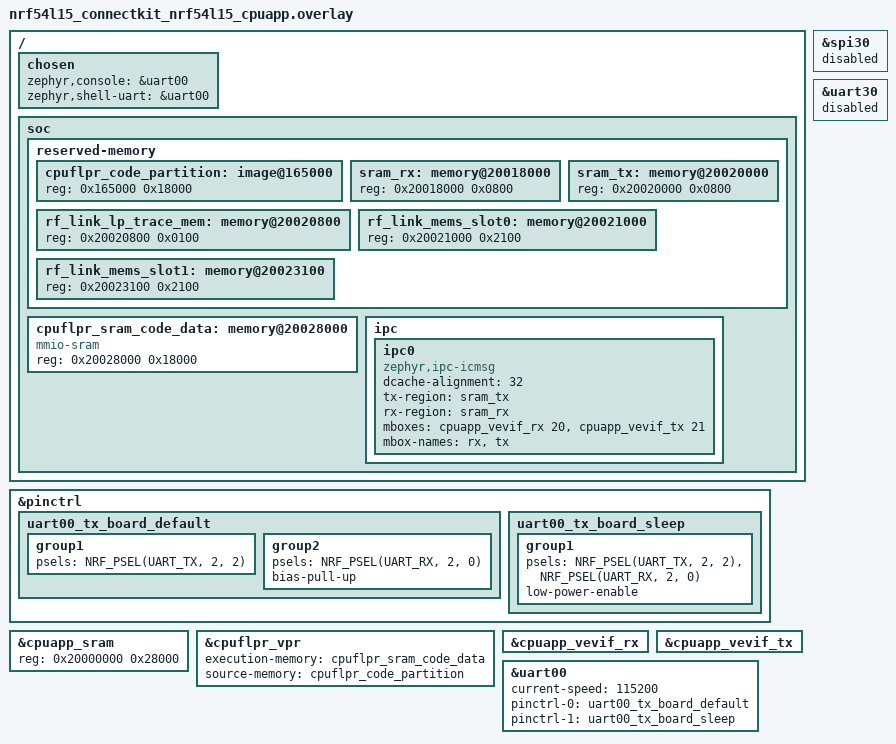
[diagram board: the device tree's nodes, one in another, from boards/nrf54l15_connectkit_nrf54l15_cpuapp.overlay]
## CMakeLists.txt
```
#
# Copyright (c) 2018 Nordic Semiconductor
# Copyright (c) 2016-2025 Makerdiary <https://makerdiary.com>
#
# SPDX-License-Identifier: LicenseRef-Nordic-5-Clause
#
cmake_minimum_required(VERSION 3.20.0)

set(USER_CACHE_DIR "${CMAKE_BINARY_DIR}/zephyr_cache" CACHE PATH "Local build cache")
find_package(Zephyr REQUIRED HINTS $ENV{ZEPHYR_BASE})
project(rf_link_tx)

# NORDIC SDK APP START
target_sources(app PRIVATE
  src/fatal_diag.c
  src/main.c
  src/debug_uart.c
  src/ipc_bridge.c
  src/radio_link.c
)

target_include_directories(app PRIVATE
  src
  ${CMAKE_CURRENT_SOURCE_DIR}/../rf_link_common
)

# NORDIC SDK APP END
```

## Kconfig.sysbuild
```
source "share/sysbuild/Kconfig"
```

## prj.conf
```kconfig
CONFIG_SERIAL=y
CONFIG_CONSOLE=n
CONFIG_UART_CONSOLE=n
CONFIG_PRINTK=n
CONFIG_STDOUT_CONSOLE=n
CONFIG_EARLY_CONSOLE=n
CONFIG_BOOT_BANNER=n
CONFIG_NCS_BOOT_BANNER=n

# Use the non-blocking UARTE async API. On nRF this is backed by EasyDMA.
CONFIG_UART_ASYNC_API=y
CONFIG_UART_00_ASYNC=y

# The custom TX board does not rely on an external 32.768 kHz crystal.
# Match the verified gpio_demo startup clock source so CPUAPP can reach main().
CONFIG_CLOCK_CONTROL_NRF_K32SRC_RC=y
CONFIG_CLOCK_CONTROL_NRF_K32SRC_500PPM=y

CONFIG_MBOX=y
CONFIG_IPC_SERVICE=y
CONFIG_IPC_SERVICE_BACKEND_ICMSG=y
CONFIG_ASSERT=y
CONFIG_CRC=y

CONFIG_ESB=y
CONFIG_ESB_MAX_PAYLOAD_LENGTH=224
CONFIG_ESB_TX_FIFO_SIZE=16
CONFIG_ESB_RX_FIFO_SIZE=16
CONFIG_CLOCK_CONTROL=y
CONFIG_NRFX_DPPI10=y

CONFIG_MAIN_STACK_SIZE=4096
CONFIG_IPC_SERVICE_BACKEND_ICMSG_WQ_STACK_SIZE=4096
CONFIG_PBUF_RX_READ_BUF_SIZE=256
```

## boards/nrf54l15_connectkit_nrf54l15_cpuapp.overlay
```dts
/ {
	chosen {
		zephyr,console = &uart00;
		zephyr,shell-uart = &uart00;
	};

	soc {
		reserved-memory {
			#address-cells = <1>;
			#size-cells = <1>;
			ranges;

			/* FLPR code partition */
			cpuflpr_code_partition: image@165000 {
				reg = <0x165000 0x18000>; /* 96 KB */
			};

			/* ICMSG shared memory: HP receives here */
			sram_rx: memory@20018000 {
				reg = <0x20018000 0x0800>;
			};

			/* ICMSG shared memory: HP transmits here */
			sram_tx: memory@20020000 {
				reg = <0x20020000 0x0800>;
			};

			/* LP runtime trace shared with HP for diagnostics */
			rf_link_lp_trace_mem: memory@20020800 {
				reg = <0x20020800 0x0100>;
			};

			/* Ping-pong MEMS batches written by FLPR and read by CPUAPP. */
			rf_link_mems_slot0: memory@20021000 {
				reg = <0x20021000 0x2100>;
			};

			rf_link_mems_slot1: memory@20023100 {
				reg = <0x20023100 0x2100>;
			};
		};

		/* FLPR execution SRAM */
		cpuflpr_sram_code_data: memory@20028000 {
			compatible = "mmio-sram";
			reg = <0x20028000 0x18000>; /* 96 KB */
			#address-cells = <1>;
			#size-cells = <1>;
			ranges = <0x0 0x20028000 0x18000>;
		};

		ipc {
			ipc0: ipc0 {
				compatible = "zephyr,ipc-icmsg";
				dcache-alignment = <32>;
				tx-region = <&sram_tx>;
				rx-region = <&sram_rx>;
				mboxes = <&cpuapp_vevif_rx 20>, <&cpuapp_vevif_tx 21>;
				mbox-names = "rx", "tx";
				status = "okay";
			};
		};
	};
};

/* TX custom board UART: MCU_UART_RX=P2.00, MCU_UART_TX=P2.02. */
&pinctrl {
	uart00_tx_board_default: uart00_tx_board_default {
		group1 {
			psels = <NRF_PSEL(UART_TX, 2, 2)>;
		};
		group2 {
			psels = <NRF_PSEL(UART_RX, 2, 0)>;
			bias-pull-up;
		};
	};

	uart00_tx_board_sleep: uart00_tx_board_sleep {
		group1 {
			psels = <NRF_PSEL(UART_TX, 2, 2)>,
				<NRF_PSEL(UART_RX, 2, 0)>;
			low-power-enable;
		};
	};
};

&cpuapp_sram {
	reg = <0x20000000 0x28000>; /* 160 KB */
	ranges = <0x0 0x20000000 0x28000>;
};

&cpuflpr_vpr {
	status = "okay";
	execution-memory = <&cpuflpr_sram_code_data>;
	source-memory = <&cpuflpr_code_partition>;
};

&cpuapp_vevif_rx {
	status = "okay";
};

&cpuapp_vevif_tx {
	status = "okay";
};

/* Serial instance 30 is owned by FLPR as SPIM30 for IIM-42352 sampling. */
&spi30 {
	status = "disabled";
};

&uart30 {
	status = "disabled";
};

&uart00 {
	status = "okay";
	current-speed = <115200>;
	pinctrl-0 = <&uart00_tx_board_default>;
	pinctrl-1 = <&uart00_tx_board_sleep>;
	pinctrl-names = "default", "sleep";
	/delete-property/ hw-flow-control;
};
```

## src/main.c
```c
#include <errno.h>
#include <stdint.h>
#include <string.h>
#include <zephyr/cache.h>
#include <zephyr/app_version.h>
#include <zephyr/kernel.h>
#include <zephyr/sys/barrier.h>
#include <zephyr/sys/crc.h>

#include "debug_uart.h"
#include "ipc_bridge.h"
#include "lp_trace.h"
#include "mems_batch.h"
#include "radio_link.h"
#include "rf_link_proto.h"

#define BATCH_RELEASE_TIMEOUT_MS 20u
#define BATCH_RELEASE_RETRIES    3u

struct batch_tx_stats {
	uint32_t batches_received;
	uint32_t batches_sent;
	uint32_t batches_failed;
	uint32_t batch_bad_header;
	uint32_t batch_bad_crc;
	uint32_t frames_attempted;
	uint32_t frames_sent;
	uint32_t frames_failed;
	uint32_t samples_sent;
	uint32_t release_errors;
};

static struct batch_tx_stats batch_stats;
static uint16_t rf_seq;
static bool radio_ready;

static void print_boot_line(void)
{
	debug_uart_puts("\r\nrf_link_tx HP started");
	debug_uart_crlf();
	debug_uart_puts("mode=MEMS_BATCH_ESB_PTX,phy=");
	debug_uart_puts(radio_link_phy_label());
	debug_uart_puts(",ack=");
	debug_uart_puts(RF_LINK_NOACK_STREAM ? "noack" : "ack");
	debug_uart_puts(",channel=");
	debug_uart_u32(RF_LINK_CHANNEL);
	debug_uart_puts(",pipe=");
	debug_uart_u32(RF_LINK_PIPE);
	debug_uart_puts(",prefix=0x54,fw=");
	debug_uart_puts(STRINGIFY(APP_BUILD_VERSION));
	debug_uart_puts(",batch_samples=");
	debug_uart_u32(RF_LINK_MEMS_BATCH_SAMPLE_COUNT);
	debug_uart_puts(",samples_per_frame=");
	debug_uart_u32(RF_LINK_FRAME_SAMPLE_COUNT);
	debug_uart_puts(",sample_hz=");
	debug_uart_u32(RF_LINK_TARGET_SAMPLE_HZ);
	debug_uart_crlf();
}

static void print_status(void)
{
	struct ipc_bridge_stats ipc_stats;
	struct rf_link_lp_trace lp_trace;
	struct radio_link_stats radio_stats = {0};
	bool have_lp_trace;

	ipc_bridge_stats_get(&ipc_stats);
	if (radio_ready) {
		radio_link_stats_get(&radio_stats);
	}
	have_lp_trace = rf_link_lp_trace_snapshot(&lp_trace);

	debug_uart_puts("TX stat batches_rx=");
	debug_uart_u32(batch_stats.batches_received);
	debug_uart_puts(" batches_ok=");
	debug_uart_u32(batch_stats.batches_sent);
	debug_uart_puts(" batch_bad_hdr=");
	debug_uart_u32(batch_stats.batch_bad_header);
	debug_uart_puts(" batches_fail=");
	debug_uart_u32(batch_stats.batches_failed);
	debug_uart_puts(" batch_bad_crc=");
	debug_uart_u32(batch_stats.batch_bad_crc);
	debug_uart_puts(" frames_try=");
	debug_uart_u32(batch_stats.frames_attempted);
	debug_uart_puts(" frames_ok=");
	debug_uart_u32(batch_stats.frames_sent);
	debug_uart_puts(" frames_fail=");
	debug_uart_u32(batch_stats.frames_failed);
	debug_uart_puts(" samples_ok=");
	debug_uart_u32(batch_stats.samples_sent);
	debug_uart_puts(" ipc_bad=");
	debug_uart_u32(ipc_stats.bad_size + ipc_stats.bad_message);
	debug_uart_puts(" ipc_drop=");
	debug_uart_u32(ipc_stats.queue_drop);
	debug_uart_puts(" release_err=");
	debug_uart_u32(batch_stats.release_errors + ipc_stats.release_fail);
	debug_uart_puts(" rf_ok=");
	debug_uart_u32(radio_stats.tx_ok);
	debug_uart_puts(" rf_fail=");
	debug_uart_u32(radio_stats.tx_failed);
	debug_uart_puts(" rf_timeout=");
	debug_uart_u32(radio_stats.tx_timeout);
	debug_uart_puts(" mac_avg_us=");
	debug_uart_u32(radio_stats.mac_latency_avg_us);
	debug_uart_puts(" lp_stage=");
	debug_uart_u32(have_lp_trace ? lp_trace.stage : 0u);
	debug_uart_puts(" lp_batches=");
	debug_uart_u32(have_lp_trace ? lp_trace.batches_ready : 0u);
	debug_uart_puts(" lp_samples=");
	debug_uart_u32(have_lp_trace ? lp_trace.sensor_samples : 0u);
	debug_uart_puts(" lp_irq=");
	debug_uart_u32(have_lp_trace ? lp_trace.sensor_irq_count : 0u);
	debug_uart_puts(" lp_poll=");
	debug_uart_u32(have_lp_trace ? lp_trace.sensor_poll_fallbacks : 0u);
	debug_uart_puts(" lp_malformed=");
	debug_uart_u32(have_lp_trace ? lp_trace.sensor_malformed : 0u);
	debug_uart_puts(" lp_io_err=");
	debug_uart_u32(have_lp_trace ? lp_trace.sensor_io_errors : 0u);
	debug_uart_puts(" lp_fifo_ovf=");
	debug_uart_u32(have_lp_trace ? lp_trace.fifo_overflows : 0u);
	debug_uart_puts(" lp_slot_wait=");
	debug_uart_u32(have_lp_trace ? lp_trace.slot_waits : 0u);
	debug_uart_puts(" lp_fatal=");
	debug_uart_u32(have_lp_trace ? lp_trace.fatal_count : 0u);
	debug_uart_puts(" lp_fatal_reason=");
	debug_uart_u32(have_lp_trace ? lp_trace.fatal_reason : 0u);
	debug_uart_crlf();
}

static int ensure_radio_ready(void)
{
	int ret;

	if (radio_ready) {
		return 0;
	}

	ret = radio_link_init();
	if (ret == 0) {
		radio_ready = true;
		debug_uart_puts("radio ready after first MEMS batch");
		debug_uart_crlf();
	}

	return ret;
}

static bool batch_header_is_valid(
	const volatile struct rf_link_mems_batch *batch,
	const struct rf_link_ipc_message *message)
{
	return batch != NULL && message != NULL &&
	       batch->magic == RF_LINK_MEMS_BATCH_MAGIC &&
	       batch->version == RF_LINK_MEMS_BATCH_VERSION &&
	       batch->slot_index == message->slot_index &&
	       batch->batch_seq == message->batch_seq &&
	       batch->sample_count == RF_LINK_MEMS_BATCH_SAMPLE_COUNT &&
	       batch->sample_crc32 == message->sample_crc32;
}

static int transmit_batch(const struct rf_link_ipc_message *message)
{
	volatile struct rf_link_mems_batch *batch;
	const int16_t *samples;
	uint32_t crc;
	uint32_t offset = 0u;
	int first_error = 0;
	int ret;

	batch = rf_link_mems_batch_slot(message->slot_index);
	if (batch == NULL) {
		batch_stats.batch_bad_header++;
		return -EINVAL;
	}

	(void)sys_cache_data_invd_range((void *)(uintptr_t)batch, sizeof(*batch));
	barrier_dmem_fence_full();
	batch_stats.batches_received++;

	if (!batch_header_is_valid(batch, message)) {
		batch_stats.batch_bad_header++;
		return -EBADMSG;
	}

	samples = (const int16_t *)(uintptr_t)&batch->samples[0];
	crc = crc32_ieee((const uint8_t *)samples, sizeof(batch->samples));
	if (crc != message->sample_crc32) {
		batch_stats.batch_bad_crc++;
		return -EBADMSG;
	}

	ret = ensure_radio_ready();
	if (ret != 0) {
		return ret;
	}

	while (offset < RF_LINK_MEMS_BATCH_SAMPLE_COUNT) {
		struct rf_frame frame = {0};
		uint32_t remaining = RF_LINK_MEMS_BATCH_SAMPLE_COUNT - offset;
		uint32_t frame_samples = MIN(remaining, RF_LINK_FRAME_SAMPLE_COUNT);

		frame.magic = RF_LINK_MAGIC;
		frame.seq = rf_seq++;
		frame.sample_count = (uint16_t)frame_samples;
		frame.flags = RF_LINK_FRAME_FLAGS_MEMS;
		if (offset == 0u) {
			frame.flags |= RF_LINK_FRAME_FLAGS_BATCH_START;
		}
		if (frame_samples == remaining) {
			frame.flags |= RF_LINK_FRAME_FLAGS_BATCH_END;
		}
		frame.timestamp_ms = batch->capture_start_ms +
			(uint32_t)(((uint64_t)offset * 1000u) /
				   RF_LINK_TARGET_SAMPLE_HZ);
		memcpy(frame.samples, &samples[offset],
		       frame_samples * sizeof(frame.samples[0]));

		batch_stats.frames_attempted++;
		ret = radio_link_send_frame(&frame, K_MSEC(5));
		if (ret == 0) {
			batch_stats.frames_sent++;
			batch_stats.samples_sent += frame_samples;
		} else {
			batch_stats.frames_failed++;
			if (first_error == 0) {
				first_error = ret;
			}
		}
		offset += frame_samples;
	}

	if (first_error == 0) {
		batch_stats.batches_sent++;
	} else {
		batch_stats.batches_failed++;
	}

	return first_error;
}

static void release_batch(const struct rf_link_ipc_message *message)
{
	int ret = -EIO;

	for (uint32_t attempt = 0u; attempt < BATCH_RELEASE_RETRIES; attempt++) {
		ret = ipc_bridge_release_batch(message->slot_index, message->batch_seq,
					       K_MSEC(BATCH_RELEASE_TIMEOUT_MS));
		if (ret == 0) {
			return;
		}
	}

	batch_stats.release_errors++;
}

int main(void)
{
	struct rf_link_ipc_message message;
	uint32_t last_status_ms;
	int ret;

	/* The application owns uart00 directly; do not silently continue if it is unavailable. */
	if (!debug_uart_init()) {
		return -ENODEV;
	}
	print_boot_line();
	memset(&batch_stats, 0, sizeof(batch_stats));
	rf_seq = 0u;
	radio_ready = false;

	ret = ipc_bridge_init();
	if (ret != 0) {
		debug_uart_puts("ipc init failed err=");
		debug_uart_i32(ret);
		debug_uart_crlf();
		return ret;
	}

	ret = ipc_bridge_wait_bound(K_FOREVER);
	if (ret != 0) {
		debug_uart_puts("ipc bind failed err=");
		debug_uart_i32(ret);
		debug_uart_crlf();
		return ret;
	}

	debug_uart_puts("LP IPC bound; CPUAPP blocking until a 4096-sample batch is ready");
	debug_uart_crlf();
	last_status_ms = k_uptime_get_32();

	while (1) {
		ret = ipc_bridge_wait_batch(&message, K_FOREVER);
		if (ret != 0) {
			continue;
		}

		ret = transmit_batch(&message);
		if (ret != 0) {
			debug_uart_puts("batch rejected/failed seq=");
			debug_uart_u32(message.batch_seq);
			debug_uart_puts(" err=");
			debug_uart_i32(ret);
			debug_uart_crlf();
		}
		release_batch(&message);

		if ((uint32_t)(k_uptime_get_32() - last_status_ms) >=
		    RF_LINK_STATUS_PERIOD_MS) {
			print_status();
			last_status_ms = k_uptime_get_32();
		}
	}
}
```

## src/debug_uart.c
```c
#include "debug_uart.h"

#include <zephyr/kernel.h>
#include <zephyr/device.h>
#include <zephyr/devicetree.h>
#include <zephyr/drivers/uart.h>
#include <zephyr/sys/ring_buffer.h>
#include <string.h>

#define DEBUG_UART_NODE DT_NODELABEL(uart00)
#define DEBUG_UART_FIFO_SIZE 4096U
#define DEBUG_UART_DMA_CHUNK_SIZE 256U

static const struct device *const uart_dev = DEVICE_DT_GET_OR_NULL(DEBUG_UART_NODE);
RING_BUF_DECLARE(debug_uart_fifo, DEBUG_UART_FIFO_SIZE);
static uint8_t dma_tx_buffer[DEBUG_UART_DMA_CHUNK_SIZE];
static struct k_spinlock state_lock;
static bool ready;
static bool tx_active;

static void debug_uart_kick(void);

static void debug_uart_callback(const struct device *dev,
					struct uart_event *evt,
					void *user_data)
{
	ARG_UNUSED(dev);
	ARG_UNUSED(user_data);

	if (evt == NULL) {
		return;
	}

	if (evt->type != UART_TX_DONE && evt->type != UART_TX_ABORTED) {
		return;
	}

	k_spinlock_key_t key = k_spin_lock(&state_lock);
	tx_active = false;
	k_spin_unlock(&state_lock, key);

	/* The callback runs in interrupt context; uart_tx() is safe here. */
	debug_uart_kick();
}

static void debug_uart_kick(void)
{
	uint32_t length;
	k_spinlock_key_t key = k_spin_lock(&state_lock);

	if (!ready || tx_active || ring_buf_size_get(&debug_uart_fifo) == 0U) {
		k_spin_unlock(&state_lock, key);
		return;
	}

	length = ring_buf_get(&debug_uart_fifo, dma_tx_buffer,
				     sizeof(dma_tx_buffer));
	if (length == 0U) {
		k_spin_unlock(&state_lock, key);
		return;
	}

	/* Keep the DMA buffer reserved until UART_TX_DONE/UART_TX_ABORTED. */
	tx_active = true;
	k_spin_unlock(&state_lock, key);

	if (uart_tx(uart_dev, dma_tx_buffer, length, SYS_FOREVER_MS) != 0) {
		key = k_spin_lock(&state_lock);
		tx_active = false;
		k_spin_unlock(&state_lock, key);

		/* Keep the driver state consistent; the failed chunk is dropped. */
	}
}

static void debug_uart_enqueue(const uint8_t *data, size_t length)
{
	k_spinlock_key_t key;

	if (!ready || data == NULL || length == 0U) {
		return;
	}

	key = k_spin_lock(&state_lock);
	(void)ring_buf_put(&debug_uart_fifo, data, (uint32_t)length);
	k_spin_unlock(&state_lock, key);

	debug_uart_kick();
}

bool debug_uart_init(void)
{
	int ret;

	ready = (uart_dev != NULL) && device_is_ready(uart_dev);
	if (!ready) {
		return false;
	}

	ret = uart_callback_set(uart_dev, debug_uart_callback, NULL);
	if (ret != 0) {
		ready = false;
		return false;
	}

	ring_buf_reset(&debug_uart_fifo);
	tx_active = false;
	return ready;
}

bool debug_uart_ready(void)
{
	return ready;
}

void debug_uart_putc(char c)
{
	uint8_t byte = (uint8_t)c;

	debug_uart_enqueue(&byte, sizeof(byte));
}

void debug_uart_puts(const char *s)
{
	debug_uart_enqueue((const uint8_t *)s, (s == NULL) ? 0U : strlen(s));
}

void debug_uart_u32(uint32_t value)
{
	char buf[11];
	int pos = (int)sizeof(buf) - 1;

	buf[pos] = '\0';
	do {
		pos--;
		buf[pos] = (char)('0' + (value % 10u));
		value /= 10u;
	} while (value != 0u);

	debug_uart_puts(&buf[pos]);
}

void debug_uart_i32(int32_t value)
{
	if (value < 0) {
		debug_uart_putc('-');
		debug_uart_u32((uint32_t)(-value));
	} else {
		debug_uart_u32((uint32_t)value);
	}
}

void debug_uart_crlf(void)
{
	debug_uart_puts("\r\n");
}
```

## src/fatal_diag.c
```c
#include <zephyr/fatal.h>

#include "debug_uart.h"

void k_sys_fatal_error_handler(unsigned int reason, const struct arch_esf *esf)
{
	ARG_UNUSED(esf);

	(void)debug_uart_init();
	debug_uart_puts("\r\nHP fatal reason=");
	debug_uart_u32(reason);
	debug_uart_crlf();

	k_fatal_halt(reason);
}
```

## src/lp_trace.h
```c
#ifndef RF_LINK_LP_TRACE_H_
#define RF_LINK_LP_TRACE_H_

#include <stdbool.h>
#include <stdint.h>
#if defined(CONFIG_CACHE_MANAGEMENT)
#include <zephyr/cache.h>
#endif
#include <zephyr/devicetree.h>
#include <zephyr/kernel.h>
#include <zephyr/sys/barrier.h>

#define RF_LINK_LP_TRACE_MAGIC   0x4c505452u
#define RF_LINK_LP_TRACE_VERSION 2u

#define RF_LINK_LP_TRACE_NODE DT_NODELABEL(rf_link_lp_trace_mem)

#if !DT_NODE_HAS_STATUS(RF_LINK_LP_TRACE_NODE, okay)
#error "rf_link_lp_trace_mem is not enabled in devicetree"
#endif

enum rf_link_lp_stage {
	RF_LINK_LP_STAGE_RESET = 0u,
	RF_LINK_LP_STAGE_BOOT = 1u,
	RF_LINK_LP_STAGE_IPC_READY = 2u,
	RF_LINK_LP_STAGE_IPC_BOUND = 3u,
	RF_LINK_LP_STAGE_SENSOR_READY = 4u,
	RF_LINK_LP_STAGE_FILLING_BATCH = 5u,
	RF_LINK_LP_STAGE_BATCH_READY = 6u,
};

struct rf_link_lp_trace {
	uint32_t magic;
	uint32_t version;
	uint32_t boot_count;
	uint32_t fatal_count;
	uint32_t stage;
	uint32_t loop_count;
	uint32_t last_seq;
	uint32_t last_uptime_ms;
	uint32_t fatal_reason;
	int32_t last_send_ret;
	uint32_t ipc_sent;
	uint32_t ipc_busy;
	uint32_t ipc_failed;
	uint32_t ipc_released;
	uint32_t ipc_bad_release;
	uint32_t sensor_irq_count;
	uint32_t sensor_poll_fallbacks;
	uint32_t sensor_fifo_packets;
	uint32_t sensor_samples;
	uint32_t sensor_malformed;
	uint32_t sensor_io_errors;
	uint32_t batches_ready;
	uint32_t last_slot;
	uint32_t fifo_overflows;
	uint32_t slot_waits;
};

static inline volatile struct rf_link_lp_trace *rf_link_lp_trace_ptr(void)
{
	return (volatile struct rf_link_lp_trace *)(uintptr_t)
		DT_REG_ADDR(RF_LINK_LP_TRACE_NODE);
}

static inline void rf_link_lp_trace_boot(void)
{
	volatile struct rf_link_lp_trace *trace = rf_link_lp_trace_ptr();
	uint32_t boot_count = 1u;

	if (trace->magic == RF_LINK_LP_TRACE_MAGIC &&
	    trace->version == RF_LINK_LP_TRACE_VERSION) {
		boot_count = trace->boot_count + 1u;
	}

	trace->magic = RF_LINK_LP_TRACE_MAGIC;
	trace->version = RF_LINK_LP_TRACE_VERSION;
	trace->boot_count = boot_count;
	if (boot_count == 1u) {
		trace->fatal_count = 0u;
	}
	trace->stage = RF_LINK_LP_STAGE_BOOT;
	trace->loop_count = 0u;
	trace->last_seq = 0u;
	trace->last_uptime_ms = k_uptime_get_32();
	trace->fatal_reason = 0u;
	trace->last_send_ret = 0;
	trace->ipc_sent = 0u;
	trace->ipc_busy = 0u;
	trace->ipc_failed = 0u;
	trace->ipc_released = 0u;
	trace->ipc_bad_release = 0u;
	trace->sensor_irq_count = 0u;
	trace->sensor_poll_fallbacks = 0u;
	trace->sensor_fifo_packets = 0u;
	trace->sensor_samples = 0u;
	trace->sensor_malformed = 0u;
	trace->sensor_io_errors = 0u;
	trace->batches_ready = 0u;
	trace->last_slot = 0u;
	trace->fifo_overflows = 0u;
	trace->slot_waits = 0u;
	barrier_dmem_fence_full();
}

static inline void rf_link_lp_trace_set_stage(uint32_t stage)
{
	volatile struct rf_link_lp_trace *trace = rf_link_lp_trace_ptr();

	trace->stage = stage;
	trace->last_uptime_ms = k_uptime_get_32();
}

static inline void rf_link_lp_trace_note_loop(uint32_t seq)
{
	volatile struct rf_link_lp_trace *trace = rf_link_lp_trace_ptr();

	trace->stage = RF_LINK_LP_STAGE_FILLING_BATCH;
	trace->loop_count++;
	trace->last_seq = seq;
	trace->last_uptime_ms = k_uptime_get_32();
}

static inline void rf_link_lp_trace_note_ipc(uint32_t sent, uint32_t busy,
					     uint32_t failed, uint32_t released,
					     uint32_t bad_release, uint32_t slot_waits,
					     int32_t last_ret)
{
	volatile struct rf_link_lp_trace *trace = rf_link_lp_trace_ptr();

	trace->ipc_sent = sent;
	trace->ipc_busy = busy;
	trace->ipc_failed = failed;
	trace->ipc_released = released;
	trace->ipc_bad_release = bad_release;
	trace->slot_waits = slot_waits;
	trace->last_send_ret = last_ret;
	trace->last_uptime_ms = k_uptime_get_32();
}

static inline void rf_link_lp_trace_note_sensor(uint32_t irq_count,
						uint32_t poll_fallbacks,
						uint32_t fifo_packets,
						uint32_t samples,
						uint32_t malformed,
						uint32_t io_errors,
						uint32_t fifo_overflows)
{
	volatile struct rf_link_lp_trace *trace = rf_link_lp_trace_ptr();

	trace->sensor_irq_count = irq_count;
	trace->sensor_poll_fallbacks = poll_fallbacks;
	trace->sensor_fifo_packets = fifo_packets;
	trace->sensor_samples = samples;
	trace->sensor_malformed = malformed;
	trace->sensor_io_errors = io_errors;
	trace->fifo_overflows = fifo_overflows;
	trace->last_uptime_ms = k_uptime_get_32();
}

static inline void rf_link_lp_trace_note_batch(uint32_t batch_seq,
					       uint32_t slot_index)
{
	volatile struct rf_link_lp_trace *trace = rf_link_lp_trace_ptr();

	trace->stage = RF_LINK_LP_STAGE_BATCH_READY;
	trace->last_seq = batch_seq;
	trace->last_slot = slot_index;
	trace->batches_ready++;
	trace->last_uptime_ms = k_uptime_get_32();
	barrier_dmem_fence_full();
}

static inline void rf_link_lp_trace_note_fatal(uint32_t reason)
{
	volatile struct rf_link_lp_trace *trace = rf_link_lp_trace_ptr();

	trace->fatal_count++;
	trace->fatal_reason = reason;
	trace->last_uptime_ms = k_uptime_get_32();
}

static inline bool rf_link_lp_trace_snapshot(struct rf_link_lp_trace *out)
{
	volatile struct rf_link_lp_trace *trace = rf_link_lp_trace_ptr();

	if (out == NULL) {
		return false;
	}

#if defined(CONFIG_CACHE_MANAGEMENT)
	(void)sys_cache_data_invd_range((void *)(uintptr_t)trace, sizeof(*out));
#endif
	barrier_dmem_fence_full();

	out->magic = trace->magic;
	out->version = trace->version;
	out->boot_count = trace->boot_count;
	out->fatal_count = trace->fatal_count;
	out->stage = trace->stage;
	out->loop_count = trace->loop_count;
	out->last_seq = trace->last_seq;
	out->last_uptime_ms = trace->last_uptime_ms;
	out->fatal_reason = trace->fatal_reason;
	out->last_send_ret = trace->last_send_ret;
	out->ipc_sent = trace->ipc_sent;
	out->ipc_busy = trace->ipc_busy;
	out->ipc_failed = trace->ipc_failed;
	out->ipc_released = trace->ipc_released;
	out->ipc_bad_release = trace->ipc_bad_release;
	out->sensor_irq_count = trace->sensor_irq_count;
	out->sensor_poll_fallbacks = trace->sensor_poll_fallbacks;
	out->sensor_fifo_packets = trace->sensor_fifo_packets;
	out->sensor_samples = trace->sensor_samples;
	out->sensor_malformed = trace->sensor_malformed;
	out->sensor_io_errors = trace->sensor_io_errors;
	out->batches_ready = trace->batches_ready;
	out->last_slot = trace->last_slot;
	out->fifo_overflows = trace->fifo_overflows;
	out->slot_waits = trace->slot_waits;

	return out->magic == RF_LINK_LP_TRACE_MAGIC &&
	       out->version == RF_LINK_LP_TRACE_VERSION;
}

#endif /* RF_LINK_LP_TRACE_H_ */
```

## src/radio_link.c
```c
#include "radio_link.h"

#include <errno.h>
#include <string.h>
#include <zephyr/device.h>
#include <zephyr/devicetree.h>
#include <zephyr/drivers/clock_control.h>
#include <zephyr/drivers/clock_control/nrf_clock_control.h>
#include <zephyr/spinlock.h>
#include <zephyr/sys/atomic.h>
#include <esb.h>
#include <nrf.h>
#include <nrf_erratas.h>

#if defined(CONFIG_CLOCK_CONTROL_NRF2)
#include <hal/nrf_lrcconf.h>
#endif

#if NRF54L_ERRATA_20_PRESENT
#include <hal/nrf_power.h>
#endif

#if defined(NRF54LM20A_ENGA_XXAA)
#include <hal/nrf_clock.h>
#endif

BUILD_ASSERT(RF_LINK_FRAME_WIRE_SIZE <= CONFIG_ESB_MAX_PAYLOAD_LENGTH,
	     "CONFIG_ESB_MAX_PAYLOAD_LENGTH is too small for rf_frame");

#if defined(RADIO_MODE_MODE_Nrf_4Mbit_0BT6)
#define RF_LINK_ESB_BITRATE ESB_BITRATE_4MBPS
#define RF_LINK_PHY_LABEL   "4M"
#else
#define RF_LINK_ESB_BITRATE ESB_BITRATE_2MBPS
#define RF_LINK_PHY_LABEL   "2M"
#endif

static K_SEM_DEFINE(tx_done_sem, 0, 1);

static atomic_t tx_ok;
static atomic_t tx_failed;
static atomic_t tx_timeout;
static atomic_t tx_errors;
static atomic_t last_attempts;
static volatile int last_tx_result;

static struct k_spinlock latency_lock;
static uint32_t latency_count;
static uint32_t latency_last_us;
static uint32_t latency_min_us = UINT32_MAX;
static uint32_t latency_max_us;
static uint64_t latency_sum_us;

static void latency_stats_update(uint32_t latency_us)
{
	k_spinlock_key_t key = k_spin_lock(&latency_lock);

	latency_last_us = latency_us;
	if (latency_us < latency_min_us) {
		latency_min_us = latency_us;
	}
	if (latency_us > latency_max_us) {
		latency_max_us = latency_us;
	}
	latency_sum_us += latency_us;
	latency_count++;

	k_spin_unlock(&latency_lock, key);
}

static void radio_event_handler(const struct esb_evt *event)
{
	switch (event->evt_id) {
	case ESB_EVENT_TX_SUCCESS:
		last_tx_result = 0;
		atomic_inc(&tx_ok);
		atomic_set(&last_attempts, (atomic_val_t)event->tx_attempts);
		k_sem_give(&tx_done_sem);
		break;
	case ESB_EVENT_TX_FAILED:
		last_tx_result = -EIO;
		atomic_inc(&tx_failed);
		atomic_set(&last_attempts, (atomic_val_t)event->tx_attempts);
		k_sem_give(&tx_done_sem);
		break;
	case ESB_EVENT_RX_RECEIVED:
		break;
	}
}

#if defined(CONFIG_CLOCK_CONTROL_NRF)
static int clocks_start(void)
{
	int err;
	int res;
	struct onoff_manager *clk_mgr;
	struct onoff_client clk_cli;

	clk_mgr = z_nrf_clock_control_get_onoff(CLOCK_CONTROL_NRF_SUBSYS_HF);
	if (clk_mgr == NULL) {
		return -ENXIO;
	}

	sys_notify_init_spinwait(&clk_cli.notify);

	err = onoff_request(clk_mgr, &clk_cli);
	if (err < 0) {
		return err;
	}

	do {
		err = sys_notify_fetch_result(&clk_cli.notify, &res);
		if (err == 0 && res != 0) {
			return res;
		}
	} while (err != 0);

#if NRF54L_ERRATA_20_PRESENT
	if (nrf54l_errata_20()) {
		nrf_power_task_trigger(NRF_POWER, NRF_POWER_TASK_CONSTLAT);
	}
#endif

#if defined(NRF54LM20A_ENGA_XXAA)
	nrf_clock_task_trigger(NRF_CLOCK, NRF_CLOCK_TASK_PLLSTART);
#endif

	return 0;
}
#elif defined(CONFIG_CLOCK_CONTROL_NRF2)
static int clocks_start(void)
{
	int err;
	int res;
	const struct device *radio_clk_dev =
		DEVICE_DT_GET_OR_NULL(DT_CLOCKS_CTLR(DT_NODELABEL(radio)));
	struct onoff_client radio_cli;

	if (radio_clk_dev == NULL) {
		return -ENODEV;
	}

	nrf_lrcconf_poweron_force_set(NRF_LRCCONF010,
				      NRF_LRCCONF_POWER_DOMAIN_1, true);
	sys_notify_init_spinwait(&radio_cli.notify);

	err = nrf_clock_control_request(radio_clk_dev, NULL, &radio_cli);
	if (err < 0 && err != -EALREADY) {
		return err;
	}

	do {
		err = sys_notify_fetch_result(&radio_cli.notify, &res);
		if (err == 0 && res != 0) {
			return res;
		}
	} while (err == -EAGAIN);

	nrf_lrcconf_clock_always_run_force_set(NRF_LRCCONF000, 0, true);
	nrf_lrcconf_task_trigger(NRF_LRCCONF000, NRF_LRCCONF_TASK_CLKSTART_0);

	return 0;
}
#else
BUILD_ASSERT(false, "No Nordic clock control driver enabled");
#endif

int radio_link_init(void)
{
	static const uint8_t base_addr_0[4] = {0x52, 0x46, 0x4c, 0x31};
	static const uint8_t base_addr_1[4] = {0xc2, 0xc2, 0xc2, 0xc2};
	static const uint8_t addr_prefix[8] = {
		RF_LINK_PIPE_PREFIX, 0xc2, 0xc3, 0xc4,
		0xc5, 0xc6, 0xc7, 0xc8
	};
	struct esb_config config = ESB_DEFAULT_CONFIG;
	int ret;

	ret = clocks_start();
	if (ret != 0) {
		return ret;
	}

	config.protocol = ESB_PROTOCOL_ESB_DPL;
	config.mode = ESB_MODE_PTX;
	config.bitrate = RF_LINK_ESB_BITRATE;
	config.crc = ESB_CRC_16BIT;
	config.event_handler = radio_event_handler;
	config.retransmit_delay = 600;
	config.retransmit_count = 0;
	config.payload_length = RF_LINK_FRAME_WIRE_SIZE;
	config.selective_auto_ack = true;
	config.tx_mode = ESB_TXMODE_AUTO;

	ret = esb_init(&config);
	if (ret != 0) {
		return ret;
	}

	ret = esb_set_address_length(5);
	if (ret != 0) {
		return ret;
	}

	ret = esb_set_base_address_0(base_addr_0);
	if (ret != 0) {
		return ret;
	}

	ret = esb_set_base_address_1(base_addr_1);
	if (ret != 0) {
		return ret;
	}

	ret = esb_set_prefixes(addr_prefix, ARRAY_SIZE(addr_prefix));
	if (ret != 0) {
		return ret;
	}

	ret = esb_set_rf_channel(RF_LINK_CHANNEL);
	if (ret != 0) {
		return ret;
	}

	return esb_flush_tx();
}

int radio_link_send_frame(const struct rf_frame *frame, k_timeout_t timeout)
{
	struct esb_payload payload = {0};
	uint32_t start_cycles;
	uint32_t elapsed_cycles;
	int ret;

	if (frame == NULL) {
		return -EINVAL;
	}

	payload.pipe = 0;
	payload.noack = RF_LINK_NOACK_STREAM ? true : false;
	payload.length = RF_LINK_FRAME_WIRE_SIZE;
	memcpy(payload.data, frame, sizeof(*frame));

	k_sem_reset(&tx_done_sem);
	last_tx_result = -EINPROGRESS;

	start_cycles = k_cycle_get_32();

	ret = esb_write_payload(&payload);
	if (ret != 0) {
		atomic_inc(&tx_errors);
		return ret;
	}

	ret = k_sem_take(&tx_done_sem, timeout);
	elapsed_cycles = k_cycle_get_32() - start_cycles;
	latency_stats_update(k_cyc_to_us_floor32(elapsed_cycles));

	if (ret != 0) {
		atomic_inc(&tx_timeout);
		(void)esb_flush_tx();
		return -ETIMEDOUT;
	}

	return last_tx_result;
}

void radio_link_stats_get(struct radio_link_stats *stats)
{
	k_spinlock_key_t key;

	if (stats == NULL) {
		return;
	}

	stats->tx_ok = (uint32_t)atomic_get(&tx_ok);
	stats->tx_failed = (uint32_t)atomic_get(&tx_failed);
	stats->tx_timeout = (uint32_t)atomic_get(&tx_timeout);
	stats->tx_errors = (uint32_t)atomic_get(&tx_errors);
	stats->last_attempts = (uint32_t)atomic_get(&last_attempts);

	key = k_spin_lock(&latency_lock);
	stats->mac_latency_count = latency_count;
	stats->mac_latency_last_us = latency_last_us;
	stats->mac_latency_min_us = (latency_count == 0u) ? 0u : latency_min_us;
	stats->mac_latency_avg_us = (latency_count == 0u) ? 0u :
				    (uint32_t)(latency_sum_us / latency_count);
	stats->mac_latency_max_us = latency_max_us;
	k_spin_unlock(&latency_lock, key);
}

const char *radio_link_phy_label(void)
{
	return RF_LINK_PHY_LABEL;
}
```

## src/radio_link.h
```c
#ifndef RF_LINK_RADIO_LINK_H_
#define RF_LINK_RADIO_LINK_H_

#include <stdint.h>
#include <zephyr/kernel.h>

#include "rf_link_proto.h"

struct radio_link_stats {
	uint32_t tx_ok;
	uint32_t tx_failed;
	uint32_t tx_timeout;
	uint32_t tx_errors;
	uint32_t last_attempts;
	uint32_t mac_latency_count;
	uint32_t mac_latency_last_us;
	uint32_t mac_latency_min_us;
	uint32_t mac_latency_avg_us;
	uint32_t mac_latency_max_us;
};

int radio_link_init(void);
int radio_link_send_frame(const struct rf_frame *frame, k_timeout_t timeout);
void radio_link_stats_get(struct radio_link_stats *stats);
const char *radio_link_phy_label(void);

#endif /* RF_LINK_RADIO_LINK_H_ */
```
